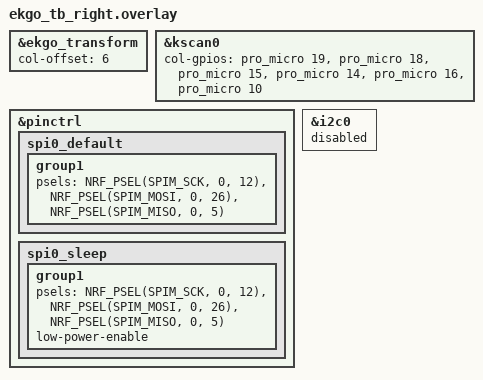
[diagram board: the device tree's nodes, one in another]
/*
 * Copyright (c) 2020 The ZMK Contributors
 *
 * SPDX-License-Identifier: MIT
 */
#include <zephyr/dt-bindings/input/input-event-codes.h>
#include "ekgo_tb.dtsi"

&ekgo_transform {
    col-offset = <6>;
};

&kscan0 {
    col-gpios
        = <&pro_micro 19 GPIO_ACTIVE_HIGH>
		, <&pro_micro 18 GPIO_ACTIVE_HIGH>
		, <&pro_micro 15 GPIO_ACTIVE_HIGH>
		, <&pro_micro 14 GPIO_ACTIVE_HIGH>
		, <&pro_micro 16 GPIO_ACTIVE_HIGH>
        , <&pro_micro 10 GPIO_ACTIVE_HIGH>
        ;
};

&pinctrl {
    spi0_default: spi0_default {
        group1 {
            psels = <NRF_PSEL(SPIM_SCK,  0, 12)>,
                    <NRF_PSEL(SPIM_MOSI, 0, 26)>,
                    <NRF_PSEL(SPIM_MISO, 0, 5)>; 
        };
    };
    spi0_sleep: spi0_sleep {
        group1 {
            psels = <NRF_PSEL(SPIM_SCK,  0, 12)>,  
                    <NRF_PSEL(SPIM_MOSI, 0, 26)>,
                    <NRF_PSEL(SPIM_MISO, 0, 5)>; 
            low-power-enable;
        };
    };
};
 
&i2c0 {
    status = "disabled";
};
